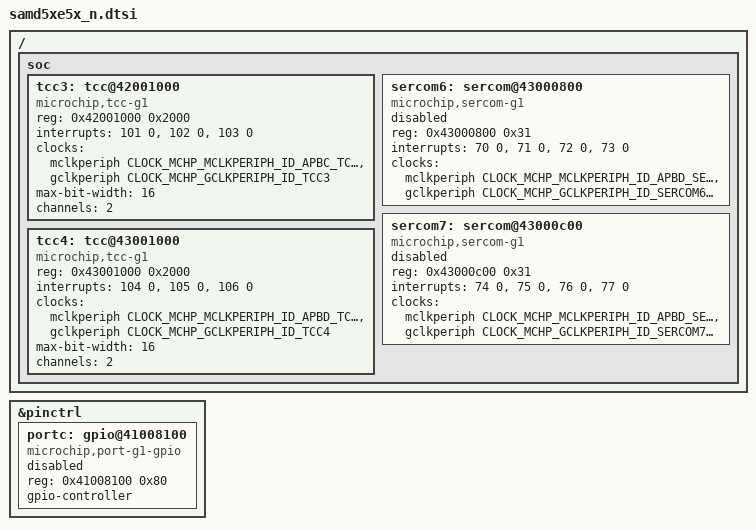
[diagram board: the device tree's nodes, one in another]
/*
 * Copyright (c) 2025 Microchip Technology Inc.
 *
 * SPDX-License-Identifier: Apache-2.0
 */

#include <microchip/sam/sam_d5x_e5x/common/samd5xe5x.dtsi>

/ {
	soc {
		tcc3: tcc@42001000 {
			compatible = "microchip,tcc-g1";
			reg = <0x42001000 0x2000>;
			interrupts = <101 0>, <102 0>, <103 0>;
			clocks = <&mclkperiph CLOCK_MCHP_MCLKPERIPH_ID_APBC_TCC3>,
				 <&gclkperiph CLOCK_MCHP_GCLKPERIPH_ID_TCC3>;
			clock-names = "mclk", "gclk";
			max-bit-width = <16>;
			channels = <2>;
		};

		sercom6: sercom@43000800 {
			compatible = "microchip,sercom-g1";
			status = "disabled";
			reg = <0x43000800 0x31>;
			interrupts = <70 0>, <71 0>, <72 0>, <73 0>;
			clocks = <&mclkperiph CLOCK_MCHP_MCLKPERIPH_ID_APBD_SERCOM6>,
				 <&gclkperiph CLOCK_MCHP_GCLKPERIPH_ID_SERCOM6_CORE>;
			clock-names = "mclk", "gclk";
		};

		sercom7: sercom@43000c00 {
			compatible = "microchip,sercom-g1";
			reg = <0x43000c00 0x31>;
			interrupts = <74 0>, <75 0>, <76 0>, <77 0>;
			interrupt-names = "source-0", "source-1", "source-2", "source-3-7";
			clocks = <&mclkperiph CLOCK_MCHP_MCLKPERIPH_ID_APBD_SERCOM7>,
				 <&gclkperiph CLOCK_MCHP_GCLKPERIPH_ID_SERCOM7_CORE>;
			clock-names = "mclk", "gclk";
			status = "disabled";
		};

		tcc4: tcc@43001000 {
			compatible = "microchip,tcc-g1";
			reg = <0x43001000 0x2000>;
			interrupts = <104 0>, <105 0>, <106 0>;
			clocks = <&mclkperiph CLOCK_MCHP_MCLKPERIPH_ID_APBD_TCC4>,
				 <&gclkperiph CLOCK_MCHP_GCLKPERIPH_ID_TCC4>;
			clock-names = "mclk", "gclk";
			max-bit-width = <16>;
			channels = <2>;
		};
	};
};

&pinctrl {
	portc: gpio@41008100 {
		compatible = "microchip,port-g1-gpio";
		reg = <0x41008100 0x80>;
		gpio-controller;
		#gpio-cells = <2>;
		#microchip,pin-cells = <2>;
		status = "disabled";
	};
};
